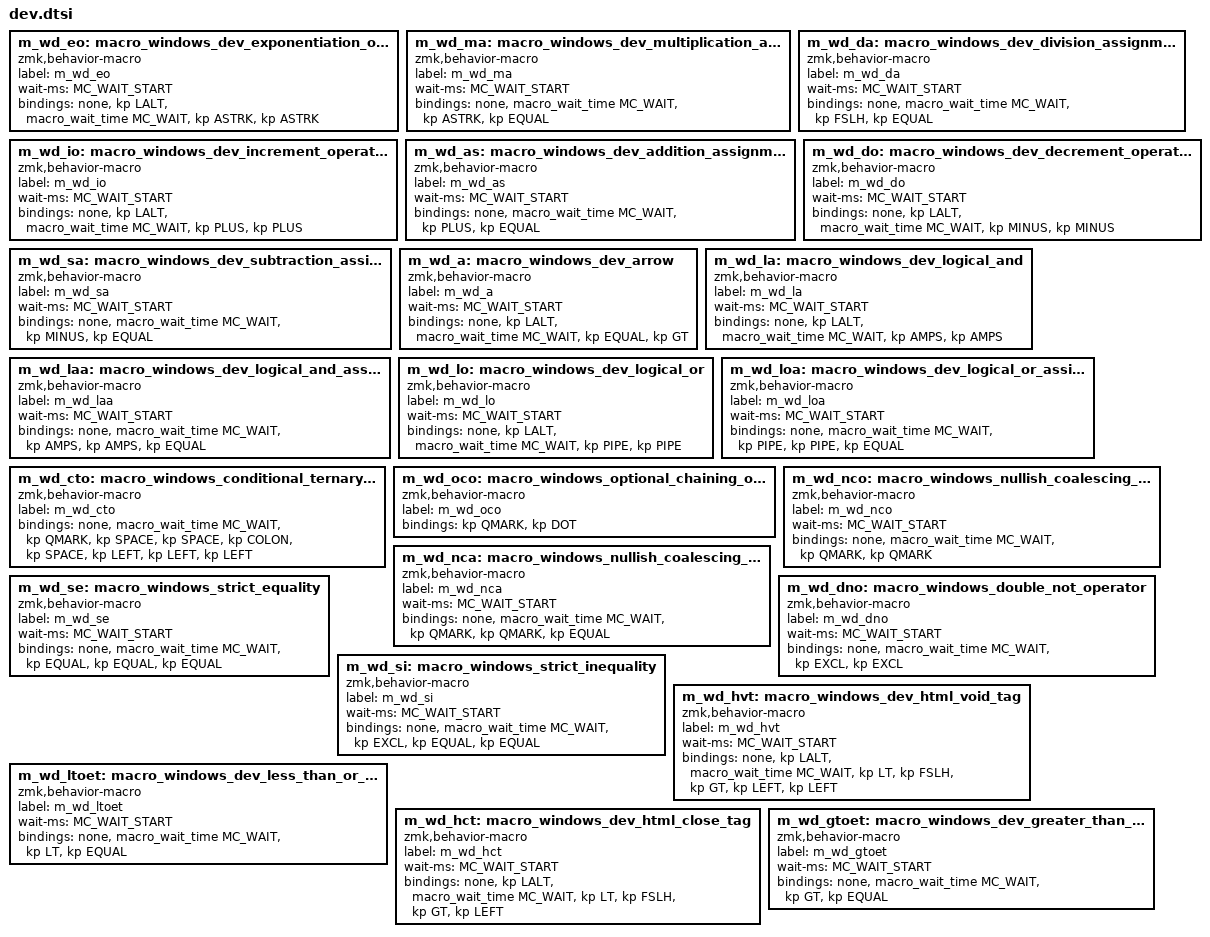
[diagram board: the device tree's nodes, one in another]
// action: **
m_wd_eo: macro_windows_dev_exponentiation_operator {
    compatible = "zmk,behavior-macro";
    label = "m_wd_eo";
    #binding-cells = <0>;
    wait-ms = <MC_WAIT_START>;
    bindings
        = <&none &kp LALT> /* ALT fix for VSCode */
        , <&macro_wait_time MC_WAIT>
        , <&kp ASTRK &kp ASTRK>;
};

// action: *=
m_wd_ma: macro_windows_dev_multiplication_assignment {
    compatible = "zmk,behavior-macro";
    label = "m_wd_ma";
    #binding-cells = <0>;
    wait-ms = <MC_WAIT_START>;
    bindings
        = <&none>
        , <&macro_wait_time MC_WAIT>
        , <&kp ASTRK &kp EQUAL>;
};

// action: /=
m_wd_da: macro_windows_dev_division_assignment {
    compatible = "zmk,behavior-macro";
    label = "m_wd_da";
    #binding-cells = <0>;
    wait-ms = <MC_WAIT_START>;
    bindings
        = <&none>
        , <&macro_wait_time MC_WAIT>
        , <&kp FSLH &kp EQUAL>;
};

// action: ++
m_wd_io: macro_windows_dev_increment_operator {
    compatible = "zmk,behavior-macro";
    label = "m_wd_io";
    #binding-cells = <0>;
    wait-ms = <MC_WAIT_START>;
    bindings
        = <&none &kp LALT> /* ALT fix for VSCode */
        , <&macro_wait_time MC_WAIT>
        , <&kp PLUS &kp PLUS>;
};

// action: +=
m_wd_as: macro_windows_dev_addition_assignment {
    compatible = "zmk,behavior-macro";
    label = "m_wd_as";
    #binding-cells = <0>;
    wait-ms = <MC_WAIT_START>;
    bindings
        = <&none>
        , <&macro_wait_time MC_WAIT>
        , <&kp PLUS &kp EQUAL>;
};

// action: --
m_wd_do: macro_windows_dev_decrement_operator {
    compatible = "zmk,behavior-macro";
    label = "m_wd_do";
    #binding-cells = <0>;
    wait-ms = <MC_WAIT_START>;
    bindings
        = <&none &kp LALT> /* ALT fix for VSCode */
        , <&macro_wait_time MC_WAIT>
        , <&kp MINUS &kp MINUS>;
};

// action: -=
m_wd_sa: macro_windows_dev_subtraction_assignment {
    compatible = "zmk,behavior-macro";
    label = "m_wd_sa";
    #binding-cells = <0>;
    wait-ms = <MC_WAIT_START>;
    bindings
        = <&none>
        , <&macro_wait_time MC_WAIT>
        , <&kp MINUS &kp EQUAL>;
};

// action: =>
m_wd_a: macro_windows_dev_arrow {
    compatible = "zmk,behavior-macro";
    label = "m_wd_a";
    #binding-cells = <0>;
    wait-ms = <MC_WAIT_START>;
    bindings
        = <&none &kp LALT> /* ALT fix for VSCode */
        , <&macro_wait_time MC_WAIT>
        , <&kp EQUAL &kp GT>;
};

// action: &&
m_wd_la: macro_windows_dev_logical_and {
    compatible = "zmk,behavior-macro";
    label = "m_wd_la";
    #binding-cells = <0>;
    wait-ms = <MC_WAIT_START>;
    bindings
        = <&none &kp LALT> /* ALT fix for VSCode */
        , <&macro_wait_time MC_WAIT>
        , <&kp AMPS &kp AMPS>;
};

// action: &&=
m_wd_laa: macro_windows_dev_logical_and_assignment {
    compatible = "zmk,behavior-macro";
    label = "m_wd_laa";
    #binding-cells = <0>;
    wait-ms = <MC_WAIT_START>;
    bindings
        = <&none>
        , <&macro_wait_time MC_WAIT>
        , <&kp AMPS &kp AMPS &kp EQUAL>;
};

// action: ||
m_wd_lo: macro_windows_dev_logical_or {
    compatible = "zmk,behavior-macro";
    label = "m_wd_lo";
    #binding-cells = <0>;
    wait-ms = <MC_WAIT_START>;
    bindings
        = <&none &kp LALT> /* ALT fix for VSCode */
        , <&macro_wait_time MC_WAIT>
        , <&kp PIPE &kp PIPE>;
};

// action: ||=
m_wd_loa: macro_windows_dev_logical_or_assignment {
    compatible = "zmk,behavior-macro";
    label = "m_wd_loa";
    #binding-cells = <0>;
    wait-ms = <MC_WAIT_START>;
    bindings
        = <&none>
        , <&macro_wait_time MC_WAIT>
        , <&kp PIPE &kp PIPE &kp EQUAL>;
};

// action: ?░:░
m_wd_cto: macro_windows_conditional_ternary_operator {
    compatible = "zmk,behavior-macro";
    label = "m_wd_cto";
    #binding-cells = <0>;
    bindings
        = <&none>
        , <&macro_wait_time MC_WAIT>
        , <&kp QMARK &kp SPACE &kp SPACE &kp COLON &kp SPACE>
        , <&kp LEFT &kp LEFT &kp LEFT>;
};

// action: ?.
m_wd_oco: macro_windows_optional_chaining_operator {
    compatible = "zmk,behavior-macro";
    label = "m_wd_oco";
    #binding-cells = <0>;
    bindings
        = <&kp QMARK &kp DOT>;
};

// action: ??
m_wd_nco: macro_windows_nullish_coalescing_operator {
    compatible = "zmk,behavior-macro";
    label = "m_wd_nco";
    #binding-cells = <0>;
    wait-ms = <MC_WAIT_START>;
    bindings
        = <&none>
        , <&macro_wait_time MC_WAIT>
        , <&kp QMARK &kp QMARK>;
};

// action: ??=
m_wd_nca: macro_windows_nullish_coalescing_assignment {
    compatible = "zmk,behavior-macro";
    label = "m_wd_nca";
    #binding-cells = <0>;
    wait-ms = <MC_WAIT_START>;
    bindings
        = <&none>
        , <&macro_wait_time MC_WAIT>
        , <&kp QMARK &kp QMARK &kp EQUAL>;
};

// action: ===
m_wd_se: macro_windows_strict_equality {
    compatible = "zmk,behavior-macro";
    label = "m_wd_se";
    #binding-cells = <0>;
    wait-ms = <MC_WAIT_START>;
    bindings
        = <&none>
        , <&macro_wait_time MC_WAIT>
        , <&kp EQUAL &kp EQUAL &kp EQUAL>;
};

// action: !!
m_wd_dno: macro_windows_double_not_operator {
    compatible = "zmk,behavior-macro";
    label = "m_wd_dno";
    #binding-cells = <0>;
    wait-ms = <MC_WAIT_START>;
    bindings
        = <&none>
        , <&macro_wait_time MC_WAIT>
        , <&kp EXCL &kp EXCL>;
};

// action: !==
m_wd_si: macro_windows_strict_inequality {
    compatible = "zmk,behavior-macro";
    label = "m_wd_si";
    #binding-cells = <0>;
    wait-ms = <MC_WAIT_START>;
    bindings
        = <&none>
        , <&macro_wait_time MC_WAIT>
        , <&kp EXCL &kp EQUAL &kp EQUAL>;
};

// action: <░/>
m_wd_hvt: macro_windows_dev_html_void_tag {
    compatible = "zmk,behavior-macro";
    label = "m_wd_hvt";
    #binding-cells = <0>;
    wait-ms = <MC_WAIT_START>;
    bindings
        = <&none &kp LALT> /* ALT fix for VSCode */
        , <&macro_wait_time MC_WAIT>
        , <&kp LT &kp FSLH &kp GT>
        , <&kp LEFT &kp LEFT>;
};

// action: <=
m_wd_ltoet: macro_windows_dev_less_than_or_equal_to {
    compatible = "zmk,behavior-macro";
    label = "m_wd_ltoet";
    #binding-cells = <0>;
    wait-ms = <MC_WAIT_START>;
    bindings
        = <&none>
        , <&macro_wait_time MC_WAIT>
        , <&kp LT &kp EQUAL>;
};

// action: </░>
m_wd_hct: macro_windows_dev_html_close_tag {
    compatible = "zmk,behavior-macro";
    label = "m_wd_hct";
    #binding-cells = <0>;
    wait-ms = <MC_WAIT_START>;
    bindings
        = <&none &kp LALT> /* ALT fix for VSCode */
        , <&macro_wait_time MC_WAIT>
        , <&kp LT &kp FSLH &kp GT>
        , <&kp LEFT>;
};

// action: >=
m_wd_gtoet: macro_windows_dev_greater_than_or_equal_to {
    compatible = "zmk,behavior-macro";
    label = "m_wd_gtoet";
    #binding-cells = <0>;
    wait-ms = <MC_WAIT_START>;
    bindings
        = <&none>
        , <&macro_wait_time MC_WAIT>
        , <&kp GT &kp EQUAL>;
};
